# PCIE0_CORE_ECC_AGGR0 register map
Vendor: Texas Instruments
Peripheral module from a debugger description file (folder J7ES).
Registers are 32-bit, access not given, reset 0x0 unless marked. A register's access mark holds for its fields unless they carry their own. Offsets are as the file gives them; lines under a group give offsets from that group; [hi:lo] are bit positions; {n}, {i} and the like mark numbered series; 'fields as' and 'values as' point back to an identical list; <NAME> marks a mode.

## PCIE0_CORE_ECC_AGGR0
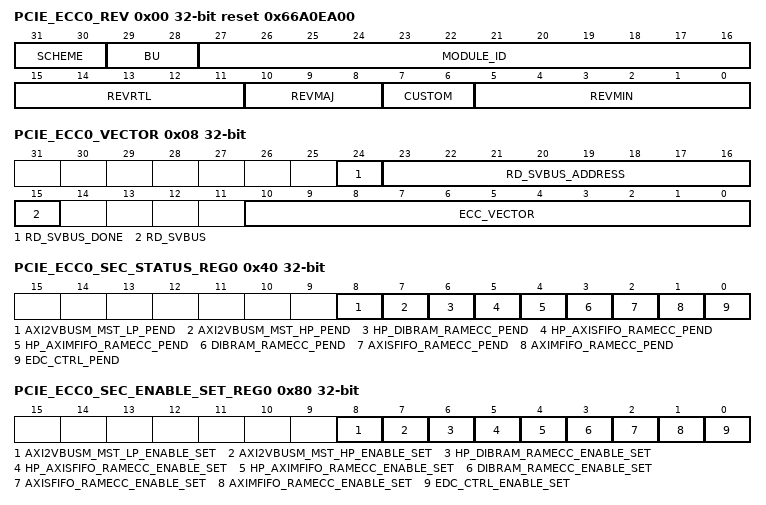
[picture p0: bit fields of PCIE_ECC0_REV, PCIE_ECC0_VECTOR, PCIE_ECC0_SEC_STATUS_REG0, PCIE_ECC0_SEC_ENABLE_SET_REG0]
0x00 PCIE_ECC0_REV ro reset 0x66A0EA00 — Revision parameters
  [31:30] SCHEME
  [29:28] BU
  [27:16] MODULE_ID
  [15:11] REVRTL — RTL version
  [10:8] REVMAJ — Major version
  [7:6] CUSTOM — Custom version
  [5:0] REVMIN — Minor version
0x08 PCIE_ECC0_VECTOR — ECC Register
  [24] RD_SVBUS_DONE — Status to indicate if read on serial VBUS is complete, write of any value will clear this bit. (access RW1C)
  [23:16] RD_SVBUS_ADDRESS rw — Read address
  [15] RD_SVBUS — Write 1 to trigger a read on the serial VBUS (access RW1S)
  [10:0] ECC_VECTOR rw — Value written to select the corresponding ECC RAM for control or status
0x0C PCIE_ECC0_STAT ro reset 0x9 — Misc Status
  [10:0] NUM_RAMS — Indicates the number of RAMS serviced by the ECC aggregator
0x10 PCIE_ECC0_RESERVED_SVBUS_y rw — Reference other documents that contain the ECC RAM wrapper and EDC controller serial vbus register sets. Offset = 10h + (y * 4h); where y = 0h to 7h
  [31:0] DATA — Serial VBUS register data
0x3C PCIE_ECC0_SEC_EOI_REG — EOI Register
  [0] EOI_WR — EOI Register (access RW1S)
0x40 PCIE_ECC0_SEC_STATUS_REG0 — Interrupt Status Register 0
  [8] AXI2VBUSM_MST_LP_PEND — Interrupt Pending Status for axi2vbusm_mst_lp_pend (access RW1S)
  [7] AXI2VBUSM_MST_HP_PEND — Interrupt Pending Status for axi2vbusm_mst_hp_pend (access RW1S)
  [6] HP_DIBRAM_RAMECC_PEND — Interrupt Pending Status for hp_dibram_ramecc_pend (access RW1S)
  [5] HP_AXISFIFO_RAMECC_PEND — Interrupt Pending Status for hp_axisfifo_ramecc_pend (access RW1S)
  [4] HP_AXIMFIFO_RAMECC_PEND — Interrupt Pending Status for hp_aximfifo_ramecc_pend (access RW1S)
  [3] DIBRAM_RAMECC_PEND — Interrupt Pending Status for dibram_ramecc_pend (access RW1S)
  [2] AXISFIFO_RAMECC_PEND — Interrupt Pending Status for axisfifo_ramecc_pend (access RW1S)
  [1] AXIMFIFO_RAMECC_PEND — Interrupt Pending Status for aximfifo_ramecc_pend (access RW1S)
  [0] EDC_CTRL_PEND — Interrupt Pending Status for edc_ctrl_pend (access RW1S)
0x80 PCIE_ECC0_SEC_ENABLE_SET_REG0 — Interrupt Enable Set Register 0
  [8] AXI2VBUSM_MST_LP_ENABLE_SET — Interrupt Enable Set Register for axi2vbusm_mst_lp_pend (access RW1S)
  [7] AXI2VBUSM_MST_HP_ENABLE_SET — Interrupt Enable Set Register for axi2vbusm_mst_hp_pend (access RW1S)
  [6] HP_DIBRAM_RAMECC_ENABLE_SET — Interrupt Enable Set Register for hp_dibram_ramecc_pend (access RW1S)
  [5] HP_AXISFIFO_RAMECC_ENABLE_SET — Interrupt Enable Set Register for hp_axisfifo_ramecc_pend (access RW1S)
  [4] HP_AXIMFIFO_RAMECC_ENABLE_SET — Interrupt Enable Set Register for hp_aximfifo_ramecc_pend (access RW1S)
  [3] DIBRAM_RAMECC_ENABLE_SET — Interrupt Enable Set Register for dibram_ramecc_pend (access RW1S)
  [2] AXISFIFO_RAMECC_ENABLE_SET — Interrupt Enable Set Register for axisfifo_ramecc_pend (access RW1S)
  [1] AXIMFIFO_RAMECC_ENABLE_SET — Interrupt Enable Set Register for aximfifo_ramecc_pend (access RW1S)
  [0] EDC_CTRL_ENABLE_SET — Interrupt Enable Set Register for edc_ctrl_pend (access RW1S)
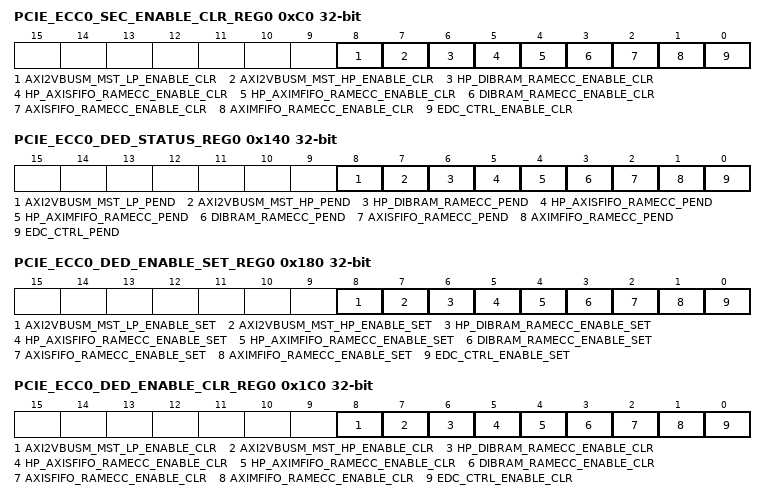
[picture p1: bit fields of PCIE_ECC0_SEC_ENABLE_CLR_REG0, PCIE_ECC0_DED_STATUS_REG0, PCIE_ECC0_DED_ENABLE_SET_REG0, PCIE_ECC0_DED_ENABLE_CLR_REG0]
0xC0 PCIE_ECC0_SEC_ENABLE_CLR_REG0 — Interrupt Enable Clear Register 0
  [8] AXI2VBUSM_MST_LP_ENABLE_CLR — Interrupt Enable Clear Register for axi2vbusm_mst_lp_pend (access RW1C)
  [7] AXI2VBUSM_MST_HP_ENABLE_CLR — Interrupt Enable Clear Register for axi2vbusm_mst_hp_pend (access RW1C)
  [6] HP_DIBRAM_RAMECC_ENABLE_CLR — Interrupt Enable Clear Register for hp_dibram_ramecc_pend (access RW1C)
  [5] HP_AXISFIFO_RAMECC_ENABLE_CLR — Interrupt Enable Clear Register for hp_axisfifo_ramecc_pend (access RW1C)
  [4] HP_AXIMFIFO_RAMECC_ENABLE_CLR — Interrupt Enable Clear Register for hp_aximfifo_ramecc_pend (access RW1C)
  [3] DIBRAM_RAMECC_ENABLE_CLR — Interrupt Enable Clear Register for dibram_ramecc_pend (access RW1C)
  [2] AXISFIFO_RAMECC_ENABLE_CLR — Interrupt Enable Clear Register for axisfifo_ramecc_pend (access RW1C)
  [1] AXIMFIFO_RAMECC_ENABLE_CLR — Interrupt Enable Clear Register for aximfifo_ramecc_pend (access RW1C)
  [0] EDC_CTRL_ENABLE_CLR — Interrupt Enable Clear Register for edc_ctrl_pend (access RW1C)
0x13C PCIE_ECC0_DED_EOI_REG — EOI Register
  [0] EOI_WR — EOI Register (access RW1S)
0x140 PCIE_ECC0_DED_STATUS_REG0 — Interrupt Status Register 0
  fields as PCIE_ECC0_SEC_STATUS_REG0
0x180 PCIE_ECC0_DED_ENABLE_SET_REG0 — Interrupt Enable Set Register 0
  fields as PCIE_ECC0_SEC_ENABLE_SET_REG0
0x1C0 PCIE_ECC0_DED_ENABLE_CLR_REG0 — Interrupt Enable Clear Register 0
  fields as PCIE_ECC0_SEC_ENABLE_CLR_REG0
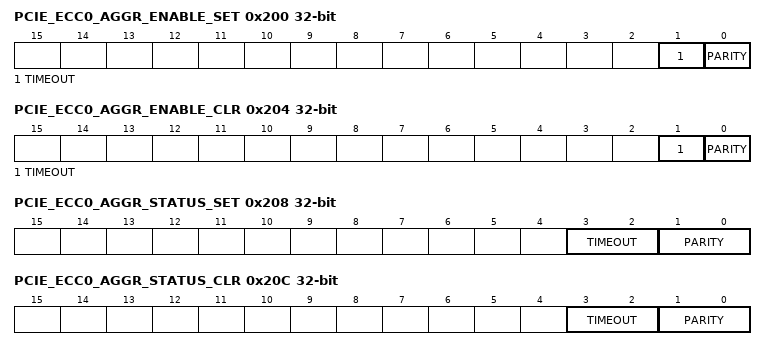
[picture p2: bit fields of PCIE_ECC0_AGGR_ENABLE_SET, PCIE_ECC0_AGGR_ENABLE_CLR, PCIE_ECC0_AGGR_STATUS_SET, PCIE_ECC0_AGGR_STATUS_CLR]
0x200 PCIE_ECC0_AGGR_ENABLE_SET — AGGR interrupt enable set Register
  [1] TIMEOUT — interrupt enable set for svbus timeout errors (access RW1S)
  [0] PARITY — interrupt enable set for parity errors (access RW1S)
0x204 PCIE_ECC0_AGGR_ENABLE_CLR — AGGR interrupt enable clear Register
  [1] TIMEOUT — interrupt enable clear for svbus timeout errors (access RW1C)
  [0] PARITY — interrupt enable clear for parity errors (access RW1C)
0x208 PCIE_ECC0_AGGR_STATUS_SET — AGGR interrupt status set Register
  [3:2] TIMEOUT — interrupt status set for svbus timeout errors (access RWincr)
  [1:0] PARITY — interrupt status set for parity errors (access RWincr)
0x20C PCIE_ECC0_AGGR_STATUS_CLR — AGGR interrupt status clear Register
  [3:2] TIMEOUT — interrupt status clear for svbus timeout errors (access RWdecr)
  [1:0] PARITY — interrupt status clear for parity errors (access RWdecr)
